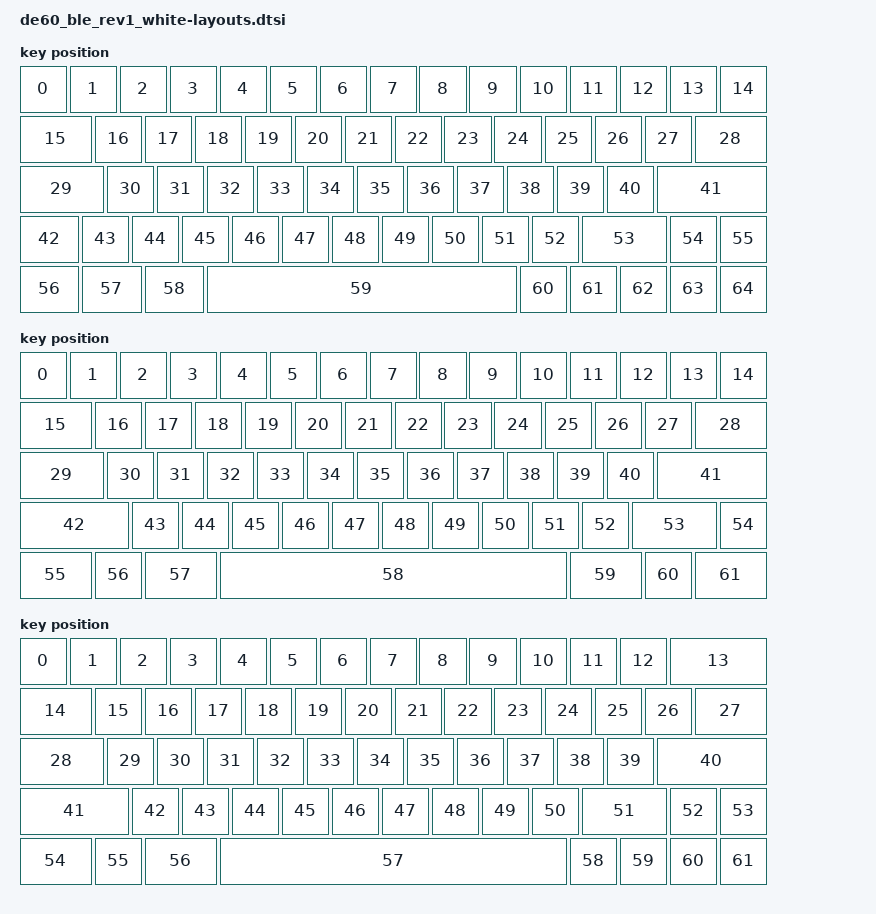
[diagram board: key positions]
#include <physical_layouts.dtsi>

/ {

    chosen {
        zmk,physical-layout = &white_ansi_625u;
    };

    white_all: white_all {
        compatible = "zmk,physical-layout";
        display-name = "WHITE All";

        kscan = <&kscan0>;
        transform = <&white_all_transform>;

        keys  //                     w   h    x    y     rot    rx    ry
            = <&key_physical_attrs 100 100    0    0       0     0     0>
            , <&key_physical_attrs 100 100  100    0       0     0     0>
            , <&key_physical_attrs 100 100  200    0       0     0     0>
            , <&key_physical_attrs 100 100  300    0       0     0     0>
            , <&key_physical_attrs 100 100  400    0       0     0     0>
            , <&key_physical_attrs 100 100  500    0       0     0     0>
            , <&key_physical_attrs 100 100  600    0       0     0     0>
            , <&key_physical_attrs 100 100  700    0       0     0     0>
            , <&key_physical_attrs 100 100  800    0       0     0     0>
            , <&key_physical_attrs 100 100  900    0       0     0     0>
            , <&key_physical_attrs 100 100 1000    0       0     0     0>
            , <&key_physical_attrs 100 100 1100    0       0     0     0>
            , <&key_physical_attrs 100 100 1200    0       0     0     0>
            , <&key_physical_attrs 100 100 1300    0       0     0     0>
            , <&key_physical_attrs 100 100 1400    0       0     0     0>
            , <&key_physical_attrs 150 100    0  100       0     0     0>
            , <&key_physical_attrs 100 100  150  100       0     0     0>
            , <&key_physical_attrs 100 100  250  100       0     0     0>
            , <&key_physical_attrs 100 100  350  100       0     0     0>
            , <&key_physical_attrs 100 100  450  100       0     0     0>
            , <&key_physical_attrs 100 100  550  100       0     0     0>
            , <&key_physical_attrs 100 100  650  100       0     0     0>
            , <&key_physical_attrs 100 100  750  100       0     0     0>
            , <&key_physical_attrs 100 100  850  100       0     0     0>
            , <&key_physical_attrs 100 100  950  100       0     0     0>
            , <&key_physical_attrs 100 100 1050  100       0     0     0>
            , <&key_physical_attrs 100 100 1150  100       0     0     0>
            , <&key_physical_attrs 100 100 1250  100       0     0     0>
            , <&key_physical_attrs 150 100 1350  100       0     0     0>
            , <&key_physical_attrs 175 100    0  200       0     0     0>
            , <&key_physical_attrs 100 100  175  200       0     0     0>
            , <&key_physical_attrs 100 100  275  200       0     0     0>
            , <&key_physical_attrs 100 100  375  200       0     0     0>
            , <&key_physical_attrs 100 100  475  200       0     0     0>
            , <&key_physical_attrs 100 100  575  200       0     0     0>
            , <&key_physical_attrs 100 100  675  200       0     0     0>
            , <&key_physical_attrs 100 100  775  200       0     0     0>
            , <&key_physical_attrs 100 100  875  200       0     0     0>
            , <&key_physical_attrs 100 100  975  200       0     0     0>
            , <&key_physical_attrs 100 100 1075  200       0     0     0>
            , <&key_physical_attrs 100 100 1175  200       0     0     0>
            , <&key_physical_attrs 225 100 1275  200       0     0     0>
            , <&key_physical_attrs 125 100    0  300       0     0     0>
            , <&key_physical_attrs 100 100  125  300       0     0     0>
            , <&key_physical_attrs 100 100  225  300       0     0     0>
            , <&key_physical_attrs 100 100  325  300       0     0     0>
            , <&key_physical_attrs 100 100  425  300       0     0     0>
            , <&key_physical_attrs 100 100  525  300       0     0     0>
            , <&key_physical_attrs 100 100  625  300       0     0     0>
            , <&key_physical_attrs 100 100  725  300       0     0     0>
            , <&key_physical_attrs 100 100  825  300       0     0     0>
            , <&key_physical_attrs 100 100  925  300       0     0     0>
            , <&key_physical_attrs 100 100 1025  300       0     0     0>
            , <&key_physical_attrs 175 100 1125  300       0     0     0>
            , <&key_physical_attrs 100 100 1300  300       0     0     0>
            , <&key_physical_attrs 100 100 1400  300       0     0     0>
            , <&key_physical_attrs 125 100    0  400       0     0     0>
            , <&key_physical_attrs 125 100  125  400       0     0     0>
            , <&key_physical_attrs 125 100  250  400       0     0     0>
            , <&key_physical_attrs 625 100  375  400       0     0     0>
            , <&key_physical_attrs 100 100 1000  400       0     0     0>
            , <&key_physical_attrs 100 100 1100  400       0     0     0>
            , <&key_physical_attrs 100 100 1200  400       0     0     0>
            , <&key_physical_attrs 100 100 1300  400       0     0     0>
            , <&key_physical_attrs 100 100 1400  400       0     0     0>
            ;
    };

    white_tsangan_split_bs_rshift: white_tsangan_split_bs_rshift {
        compatible = "zmk,physical-layout";
        display-name = "ANSI + 7U Tsangan | BS Split | Shift Tsangan";
        transform = <&white_ansi_tsangan_split_bs_rshift_transform>;

        keys  //                     w   h    x    y     rot    rx    ry
            = <&key_physical_attrs 100 100    0    0       0     0     0>
            , <&key_physical_attrs 100 100  100    0       0     0     0>
            , <&key_physical_attrs 100 100  200    0       0     0     0>
            , <&key_physical_attrs 100 100  300    0       0     0     0>
            , <&key_physical_attrs 100 100  400    0       0     0     0>
            , <&key_physical_attrs 100 100  500    0       0     0     0>
            , <&key_physical_attrs 100 100  600    0       0     0     0>
            , <&key_physical_attrs 100 100  700    0       0     0     0>
            , <&key_physical_attrs 100 100  800    0       0     0     0>
            , <&key_physical_attrs 100 100  900    0       0     0     0>
            , <&key_physical_attrs 100 100 1000    0       0     0     0>
            , <&key_physical_attrs 100 100 1100    0       0     0     0>
            , <&key_physical_attrs 100 100 1200    0       0     0     0>
            , <&key_physical_attrs 100 100 1300    0       0     0     0>
            , <&key_physical_attrs 100 100 1400    0       0     0     0>
            , <&key_physical_attrs 150 100    0  100       0     0     0>
            , <&key_physical_attrs 100 100  150  100       0     0     0>
            , <&key_physical_attrs 100 100  250  100       0     0     0>
            , <&key_physical_attrs 100 100  350  100       0     0     0>
            , <&key_physical_attrs 100 100  450  100       0     0     0>
            , <&key_physical_attrs 100 100  550  100       0     0     0>
            , <&key_physical_attrs 100 100  650  100       0     0     0>
            , <&key_physical_attrs 100 100  750  100       0     0     0>
            , <&key_physical_attrs 100 100  850  100       0     0     0>
            , <&key_physical_attrs 100 100  950  100       0     0     0>
            , <&key_physical_attrs 100 100 1050  100       0     0     0>
            , <&key_physical_attrs 100 100 1150  100       0     0     0>
            , <&key_physical_attrs 100 100 1250  100       0     0     0>
            , <&key_physical_attrs 150 100 1350  100       0     0     0>
            , <&key_physical_attrs 175 100    0  200       0     0     0>
            , <&key_physical_attrs 100 100  175  200       0     0     0>
            , <&key_physical_attrs 100 100  275  200       0     0     0>
            , <&key_physical_attrs 100 100  375  200       0     0     0>
            , <&key_physical_attrs 100 100  475  200       0     0     0>
            , <&key_physical_attrs 100 100  575  200       0     0     0>
            , <&key_physical_attrs 100 100  675  200       0     0     0>
            , <&key_physical_attrs 100 100  775  200       0     0     0>
            , <&key_physical_attrs 100 100  875  200       0     0     0>
            , <&key_physical_attrs 100 100  975  200       0     0     0>
            , <&key_physical_attrs 100 100 1075  200       0     0     0>
            , <&key_physical_attrs 100 100 1175  200       0     0     0>
            , <&key_physical_attrs 225 100 1275  200       0     0     0>
            , <&key_physical_attrs 225 100    0  300       0     0     0>
            , <&key_physical_attrs 100 100  225  300       0     0     0>
            , <&key_physical_attrs 100 100  325  300       0     0     0>
            , <&key_physical_attrs 100 100  425  300       0     0     0>
            , <&key_physical_attrs 100 100  525  300       0     0     0>
            , <&key_physical_attrs 100 100  625  300       0     0     0>
            , <&key_physical_attrs 100 100  725  300       0     0     0>
            , <&key_physical_attrs 100 100  825  300       0     0     0>
            , <&key_physical_attrs 100 100  925  300       0     0     0>
            , <&key_physical_attrs 100 100 1025  300       0     0     0>
            , <&key_physical_attrs 100 100 1125  300       0     0     0>
            , <&key_physical_attrs 175 100 1225  300       0     0     0>
            , <&key_physical_attrs 100 100 1400  300       0     0     0>
            , <&key_physical_attrs 150 100    0  400       0     0     0>
            , <&key_physical_attrs 100 100  150  400       0     0     0>
            , <&key_physical_attrs 150 100  250  400       0     0     0>
            , <&key_physical_attrs 700 100  400  400       0     0     0>
            , <&key_physical_attrs 150 100 1100  400       0     0     0>
            , <&key_physical_attrs 100 100 1250  400       0     0     0>
            , <&key_physical_attrs 150 100 1350  400       0     0     0>
            ;
    };

    white_tsangan_arrow: white_tsangan_arrow {
        compatible = "zmk,physical-layout";
        display-name = "ANSI + 7U Arrow | BS 2U | Shift Arrow";

        kscan = <&kscan0>;
        transform = <&white_ansi_tsangan_arrow_transform>;

        keys  //                     w   h    x    y     rot    rx    ry
            = <&key_physical_attrs 100 100    0    0       0     0     0>
            , <&key_physical_attrs 100 100  100    0       0     0     0>
            , <&key_physical_attrs 100 100  200    0       0     0     0>
            , <&key_physical_attrs 100 100  300    0       0     0     0>
            , <&key_physical_attrs 100 100  400    0       0     0     0>
            , <&key_physical_attrs 100 100  500    0       0     0     0>
            , <&key_physical_attrs 100 100  600    0       0     0     0>
            , <&key_physical_attrs 100 100  700    0       0     0     0>
            , <&key_physical_attrs 100 100  800    0       0     0     0>
            , <&key_physical_attrs 100 100  900    0       0     0     0>
            , <&key_physical_attrs 100 100 1000    0       0     0     0>
            , <&key_physical_attrs 100 100 1100    0       0     0     0>
            , <&key_physical_attrs 100 100 1200    0       0     0     0>
            , <&key_physical_attrs 200 100 1300    0       0     0     0>
            , <&key_physical_attrs 150 100    0  100       0     0     0>
            , <&key_physical_attrs 100 100  150  100       0     0     0>
            , <&key_physical_attrs 100 100  250  100       0     0     0>
            , <&key_physical_attrs 100 100  350  100       0     0     0>
            , <&key_physical_attrs 100 100  450  100       0     0     0>
            , <&key_physical_attrs 100 100  550  100       0     0     0>
            , <&key_physical_attrs 100 100  650  100       0     0     0>
            , <&key_physical_attrs 100 100  750  100       0     0     0>
            , <&key_physical_attrs 100 100  850  100       0     0     0>
            , <&key_physical_attrs 100 100  950  100       0     0     0>
            , <&key_physical_attrs 100 100 1050  100       0     0     0>
            , <&key_physical_attrs 100 100 1150  100       0     0     0>
            , <&key_physical_attrs 100 100 1250  100       0     0     0>
            , <&key_physical_attrs 150 100 1350  100       0     0     0>
            , <&key_physical_attrs 175 100    0  200       0     0     0>
            , <&key_physical_attrs 100 100  175  200       0     0     0>
            , <&key_physical_attrs 100 100  275  200       0     0     0>
            , <&key_physical_attrs 100 100  375  200       0     0     0>
            , <&key_physical_attrs 100 100  475  200       0     0     0>
            , <&key_physical_attrs 100 100  575  200       0     0     0>
            , <&key_physical_attrs 100 100  675  200       0     0     0>
            , <&key_physical_attrs 100 100  775  200       0     0     0>
            , <&key_physical_attrs 100 100  875  200       0     0     0>
            , <&key_physical_attrs 100 100  975  200       0     0     0>
            , <&key_physical_attrs 100 100 1075  200       0     0     0>
            , <&key_physical_attrs 100 100 1175  200       0     0     0>
            , <&key_physical_attrs 225 100 1275  200       0     0     0>
            , <&key_physical_attrs 225 100    0  300       0     0     0>
            , <&key_physical_attrs 100 100  225  300       0     0     0>
            , <&key_physical_attrs 100 100  325  300       0     0     0>
            , <&key_physical_attrs 100 100  425  300       0     0     0>
            , <&key_physical_attrs 100 100  525  300       0     0     0>
            , <&key_physical_attrs 100 100  625  300       0     0     0>
            , <&key_physical_attrs 100 100  725  300       0     0     0>
            , <&key_physical_attrs 100 100  825  300       0     0     0>
            , <&key_physical_attrs 100 100  925  300       0     0     0>
            , <&key_physical_attrs 100 100 1025  300       0     0     0>
            , <&key_physical_attrs 175 100 1125  300       0     0     0>
            , <&key_physical_attrs 100 100 1300  300       0     0     0>
            , <&key_physical_attrs 100 100 1400  300       0     0     0>
            , <&key_physical_attrs 150 100    0  400       0     0     0>
            , <&key_physical_attrs 100 100  150  400       0     0     0>
            , <&key_physical_attrs 150 100  250  400       0     0     0>
            , <&key_physical_attrs 700 100  400  400       0     0     0>
            , <&key_physical_attrs 100 100 1100  400       0     0     0>
            , <&key_physical_attrs 100 100 1200  400       0     0     0>
            , <&key_physical_attrs 100 100 1300  400       0     0     0>
            , <&key_physical_attrs 100 100 1400  400       0     0     0>
            ;
    };

    white_tsangan_arrow_split_bs: white_tsangan_arrow_split_bs {
        compatible = "zmk,physical-layout";
        display-name = "ANSI + 7U Arrow | BS Split | Shift Arrow";

        kscan = <&kscan0>;
        transform = <&white_ansi_tsangan_arrow_split_bs_transform>;

        keys  //                     w   h    x    y     rot    rx    ry
            = <&key_physical_attrs 100 100    0    0       0     0     0>
            , <&key_physical_attrs 100 100  100    0       0     0     0>
            , <&key_physical_attrs 100 100  200    0       0     0     0>
            , <&key_physical_attrs 100 100  300    0       0     0     0>
            , <&key_physical_attrs 100 100  400    0       0     0     0>
            , <&key_physical_attrs 100 100  500    0       0     0     0>
            , <&key_physical_attrs 100 100  600    0       0     0     0>
            , <&key_physical_attrs 100 100  700    0       0     0     0>
            , <&key_physical_attrs 100 100  800    0       0     0     0>
            , <&key_physical_attrs 100 100  900    0       0     0     0>
            , <&key_physical_attrs 100 100 1000    0       0     0     0>
            , <&key_physical_attrs 100 100 1100    0       0     0     0>
            , <&key_physical_attrs 100 100 1200    0       0     0     0>
            , <&key_physical_attrs 100 100 1300    0       0     0     0>
            , <&key_physical_attrs 100 100 1400    0       0     0     0>
            , <&key_physical_attrs 150 100    0  100       0     0     0>
            , <&key_physical_attrs 100 100  150  100       0     0     0>
            , <&key_physical_attrs 100 100  250  100       0     0     0>
            , <&key_physical_attrs 100 100  350  100       0     0     0>
            , <&key_physical_attrs 100 100  450  100       0     0     0>
            , <&key_physical_attrs 100 100  550  100       0     0     0>
            , <&key_physical_attrs 100 100  650  100       0     0     0>
            , <&key_physical_attrs 100 100  750  100       0     0     0>
            , <&key_physical_attrs 100 100  850  100       0     0     0>
            , <&key_physical_attrs 100 100  950  100       0     0     0>
            , <&key_physical_attrs 100 100 1050  100       0     0     0>
            , <&key_physical_attrs 100 100 1150  100       0     0     0>
            , <&key_physical_attrs 100 100 1250  100       0     0     0>
            , <&key_physical_attrs 150 100 1350  100       0     0     0>
            , <&key_physical_attrs 175 100    0  200       0     0     0>
            , <&key_physical_attrs 100 100  175  200       0     0     0>
            , <&key_physical_attrs 100 100  275  200       0     0     0>
            , <&key_physical_attrs 100 100  375  200       0     0     0>
            , <&key_physical_attrs 100 100  475  200       0     0     0>
            , <&key_physical_attrs 100 100  575  200       0     0     0>
            , <&key_physical_attrs 100 100  675  200       0     0     0>
            , <&key_physical_attrs 100 100  775  200       0     0     0>
            , <&key_physical_attrs 100 100  875  200       0     0     0>
            , <&key_physical_attrs 100 100  975  200       0     0     0>
            , <&key_physical_attrs 100 100 1075  200       0     0     0>
            , <&key_physical_attrs 100 100 1175  200       0     0     0>
            , <&key_physical_attrs 225 100 1275  200       0     0     0>
            , <&key_physical_attrs 225 100    0  300       0     0     0>
            , <&key_physical_attrs 100 100  225  300       0     0     0>
            , <&key_physical_attrs 100 100  325  300       0     0     0>
            , <&key_physical_attrs 100 100  425  300       0     0     0>
            , <&key_physical_attrs 100 100  525  300       0     0     0>
            , <&key_physical_attrs 100 100  625  300       0     0     0>
            , <&key_physical_attrs 100 100  725  300       0     0     0>
            , <&key_physical_attrs 100 100  825  300       0     0     0>
            , <&key_physical_attrs 100 100  925  300       0     0     0>
            , <&key_physical_attrs 100 100 1025  300       0     0     0>
            , <&key_physical_attrs 175 100 1125  300       0     0     0>
            , <&key_physical_attrs 100 100 1300  300       0     0     0>
            , <&key_physical_attrs 100 100 1400  300       0     0     0>
            , <&key_physical_attrs 150 100    0  400       0     0     0>
            , <&key_physical_attrs 100 100  150  400       0     0     0>
            , <&key_physical_attrs 150 100  250  400       0     0     0>
            , <&key_physical_attrs 700 100  400  400       0     0     0>
            , <&key_physical_attrs 100 100 1100  400       0     0     0>
            , <&key_physical_attrs 100 100 1200  400       0     0     0>
            , <&key_physical_attrs 100 100 1300  400       0     0     0>
            , <&key_physical_attrs 100 100 1400  400       0     0     0>
            ;
    };

    white_ansi: white_ansi {
        compatible = "zmk,physical-layout";
        display-name = "ANSI + 6.25U Universal | BS 2U | Shift Universal";

        kscan = <&kscan0>;
        transform = <&white_ansi_transform>;

        keys  //                     w   h    x    y     rot    rx    ry
            = <&key_physical_attrs 100 100    0    0       0     0     0>
            , <&key_physical_attrs 100 100  100    0       0     0     0>
            , <&key_physical_attrs 100 100  200    0       0     0     0>
            , <&key_physical_attrs 100 100  300    0       0     0     0>
            , <&key_physical_attrs 100 100  400    0       0     0     0>
            , <&key_physical_attrs 100 100  500    0       0     0     0>
            , <&key_physical_attrs 100 100  600    0       0     0     0>
            , <&key_physical_attrs 100 100  700    0       0     0     0>
            , <&key_physical_attrs 100 100  800    0       0     0     0>
            , <&key_physical_attrs 100 100  900    0       0     0     0>
            , <&key_physical_attrs 100 100 1000    0       0     0     0>
            , <&key_physical_attrs 100 100 1100    0       0     0     0>
            , <&key_physical_attrs 100 100 1200    0       0     0     0>
            , <&key_physical_attrs 200 100 1300    0       0     0     0>
            , <&key_physical_attrs 150 100    0  100       0     0     0>
            , <&key_physical_attrs 100 100  150  100       0     0     0>
            , <&key_physical_attrs 100 100  250  100       0     0     0>
            , <&key_physical_attrs 100 100  350  100       0     0     0>
            , <&key_physical_attrs 100 100  450  100       0     0     0>
            , <&key_physical_attrs 100 100  550  100       0     0     0>
            , <&key_physical_attrs 100 100  650  100       0     0     0>
            , <&key_physical_attrs 100 100  750  100       0     0     0>
            , <&key_physical_attrs 100 100  850  100       0     0     0>
            , <&key_physical_attrs 100 100  950  100       0     0     0>
            , <&key_physical_attrs 100 100 1050  100       0     0     0>
            , <&key_physical_attrs 100 100 1150  100       0     0     0>
            , <&key_physical_attrs 100 100 1250  100       0     0     0>
            , <&key_physical_attrs 150 100 1350  100       0     0     0>
            , <&key_physical_attrs 175 100    0  200       0     0     0>
            , <&key_physical_attrs 100 100  175  200       0     0     0>
            , <&key_physical_attrs 100 100  275  200       0     0     0>
            , <&key_physical_attrs 100 100  375  200       0     0     0>
            , <&key_physical_attrs 100 100  475  200       0     0     0>
            , <&key_physical_attrs 100 100  575  200       0     0     0>
            , <&key_physical_attrs 100 100  675  200       0     0     0>
            , <&key_physical_attrs 100 100  775  200       0     0     0>
            , <&key_physical_attrs 100 100  875  200       0     0     0>
            , <&key_physical_attrs 100 100  975  200       0     0     0>
            , <&key_physical_attrs 100 100 1075  200       0     0     0>
            , <&key_physical_attrs 100 100 1175  200       0     0     0>
            , <&key_physical_attrs 225 100 1275  200       0     0     0>
            , <&key_physical_attrs 225 100    0  300       0     0     0>
            , <&key_physical_attrs 100 100  225  300       0     0     0>
            , <&key_physical_attrs 100 100  325  300       0     0     0>
            , <&key_physical_attrs 100 100  425  300       0     0     0>
            , <&key_physical_attrs 100 100  525  300       0     0     0>
            , <&key_physical_attrs 100 100  625  300       0     0     0>
            , <&key_physical_attrs 100 100  725  300       0     0     0>
            , <&key_physical_attrs 100 100  825  300       0     0     0>
            , <&key_physical_attrs 100 100  925  300       0     0     0>
            , <&key_physical_attrs 100 100 1025  300       0     0     0>
            , <&key_physical_attrs 100 100 1125  300       0     0     0>
            , <&key_physical_attrs 275 100 1225  300       0     0     0>
            , <&key_physical_attrs 125 100    0  400       0     0     0>
            , <&key_physical_attrs 125 100  125  400       0     0     0>
            , <&key_physical_attrs 125 100  250  400       0     0     0>
            , <&key_physical_attrs 625 100  375  400       0     0     0>
            , <&key_physical_attrs 125 100 1000  400       0     0     0>
            , <&key_physical_attrs 125 100 1125  400       0     0     0>
            , <&key_physical_attrs 125 100 1250  400       0     0     0>
            , <&key_physical_attrs 125 100 1375  400       0     0     0>
            ;
    };

    white_ansi_split_rshift: white_ansi_split_rshift {
        compatible = "zmk,physical-layout";
        display-name = "ANSI + 6.25U Universal | BS 2U | Shift Arrow";

        kscan = <&kscan0>;
        transform = <&white_ansi_split_rshift_transform>;

        keys  //                     w   h    x    y     rot    rx    ry
            = <&key_physical_attrs 100 100    0    0       0     0     0>
            , <&key_physical_attrs 100 100  100    0       0     0     0>
            , <&key_physical_attrs 100 100  200    0       0     0     0>
            , <&key_physical_attrs 100 100  300    0       0     0     0>
            , <&key_physical_attrs 100 100  400    0       0     0     0>
            , <&key_physical_attrs 100 100  500    0       0     0     0>
            , <&key_physical_attrs 100 100  600    0       0     0     0>
            , <&key_physical_attrs 100 100  700    0       0     0     0>
            , <&key_physical_attrs 100 100  800    0       0     0     0>
            , <&key_physical_attrs 100 100  900    0       0     0     0>
            , <&key_physical_attrs 100 100 1000    0       0     0     0>
            , <&key_physical_attrs 100 100 1100    0       0     0     0>
            , <&key_physical_attrs 100 100 1200    0       0     0     0>
            , <&key_physical_attrs 200 100 1300    0       0     0     0>
            , <&key_physical_attrs 150 100    0  100       0     0     0>
            , <&key_physical_attrs 100 100  150  100       0     0     0>
            , <&key_physical_attrs 100 100  250  100       0     0     0>
            , <&key_physical_attrs 100 100  350  100       0     0     0>
            , <&key_physical_attrs 100 100  450  100       0     0     0>
            , <&key_physical_attrs 100 100  550  100       0     0     0>
            , <&key_physical_attrs 100 100  650  100       0     0     0>
            , <&key_physical_attrs 100 100  750  100       0     0     0>
            , <&key_physical_attrs 100 100  850  100       0     0     0>
            , <&key_physical_attrs 100 100  950  100       0     0     0>
            , <&key_physical_attrs 100 100 1050  100       0     0     0>
            , <&key_physical_attrs 100 100 1150  100       0     0     0>
            , <&key_physical_attrs 100 100 1250  100       0     0     0>
            , <&key_physical_attrs 150 100 1350  100       0     0     0>
            , <&key_physical_attrs 175 100    0  200       0     0     0>
            , <&key_physical_attrs 100 100  175  200       0     0     0>
            , <&key_physical_attrs 100 100  275  200       0     0     0>
            , <&key_physical_attrs 100 100  375  200       0     0     0>
            , <&key_physical_attrs 100 100  475  200       0     0     0>
            , <&key_physical_attrs 100 100  575  200       0     0     0>
            , <&key_physical_attrs 100 100  675  200       0     0     0>
            , <&key_physical_attrs 100 100  775  200       0     0     0>
            , <&key_physical_attrs 100 100  875  200       0     0     0>
            , <&key_physical_attrs 100 100  975  200       0     0     0>
            , <&key_physical_attrs 100 100 1075  200       0     0     0>
            , <&key_physical_attrs 100 100 1175  200       0     0     0>
            , <&key_physical_attrs 225 100 1275  200       0     0     0>
            , <&key_physical_attrs 225 100    0  300       0     0     0>
            , <&key_physical_attrs 100 100  225  300       0     0     0>
            , <&key_physical_attrs 100 100  325  300       0     0     0>
            , <&key_physical_attrs 100 100  425  300       0     0     0>
            , <&key_physical_attrs 100 100  525  300       0     0     0>
            , <&key_physical_attrs 100 100  625  300       0     0     0>
            , <&key_physical_attrs 100 100  725  300       0     0     0>
            , <&key_physical_attrs 100 100  825  300       0     0     0>
            , <&key_physical_attrs 100 100  925  300       0     0     0>
            , <&key_physical_attrs 100 100 1025  300       0     0     0>
            , <&key_physical_attrs 100 100 1125  300       0     0     0>
            , <&key_physical_attrs 175 100 1225  300       0     0     0>
            , <&key_physical_attrs 100 100 1400  300       0     0     0>
            , <&key_physical_attrs 125 100    0  400       0     0     0>
            , <&key_physical_attrs 125 100  125  400       0     0     0>
            , <&key_physical_attrs 125 100  250  400       0     0     0>
            , <&key_physical_attrs 625 100  375  400       0     0     0>
            , <&key_physical_attrs 125 100 1000  400       0     0     0>
            , <&key_physical_attrs 125 100 1125  400       0     0     0>
            , <&key_physical_attrs 125 100 1250  400       0     0     0>
            , <&key_physical_attrs 125 100 1375  400       0     0     0>
            ;
    };

    both_ansi_10u_split_rshift: both_ansi_10u_split_rshift {
        compatible = "zmk,physical-layout";
        display-name = "ANSI + 10U Universal | BS 2U | Shift Universal";

        kscan = <&kscan0>;
        transform = <&both_ansi_10u_split_rshift_transform>;

        keys  //                     w   h    x    y     rot    rx    ry
            = <&key_physical_attrs 100 100    0    0       0     0     0>
            , <&key_physical_attrs 100 100  100    0       0     0     0>
            , <&key_physical_attrs 100 100  200    0       0     0     0>
            , <&key_physical_attrs 100 100  300    0       0     0     0>
            , <&key_physical_attrs 100 100  400    0       0     0     0>
            , <&key_physical_attrs 100 100  500    0       0     0     0>
            , <&key_physical_attrs 100 100  600    0       0     0     0>
            , <&key_physical_attrs 100 100  700    0       0     0     0>
            , <&key_physical_attrs 100 100  800    0       0     0     0>
            , <&key_physical_attrs 100 100  900    0       0     0     0>
            , <&key_physical_attrs 100 100 1000    0       0     0     0>
            , <&key_physical_attrs 100 100 1100    0       0     0     0>
            , <&key_physical_attrs 100 100 1200    0       0     0     0>
            , <&key_physical_attrs 200 100 1300    0       0     0     0>
            , <&key_physical_attrs 150 100    0  100       0     0     0>
            , <&key_physical_attrs 100 100  150  100       0     0     0>
            , <&key_physical_attrs 100 100  250  100       0     0     0>
            , <&key_physical_attrs 100 100  350  100       0     0     0>
            , <&key_physical_attrs 100 100  450  100       0     0     0>
            , <&key_physical_attrs 100 100  550  100       0     0     0>
            , <&key_physical_attrs 100 100  650  100       0     0     0>
            , <&key_physical_attrs 100 100  750  100       0     0     0>
            , <&key_physical_attrs 100 100  850  100       0     0     0>
            , <&key_physical_attrs 100 100  950  100       0     0     0>
            , <&key_physical_attrs 100 100 1050  100       0     0     0>
            , <&key_physical_attrs 100 100 1150  100       0     0     0>
            , <&key_physical_attrs 100 100 1250  100       0     0     0>
            , <&key_physical_attrs 150 100 1350  100       0     0     0>
            , <&key_physical_attrs 175 100    0  200       0     0     0>
            , <&key_physical_attrs 100 100  175  200       0     0     0>
            , <&key_physical_attrs 100 100  275  200       0     0     0>
            , <&key_physical_attrs 100 100  375  200       0     0     0>
            , <&key_physical_attrs 100 100  475  200       0     0     0>
            , <&key_physical_attrs 100 100  575  200       0     0     0>
            , <&key_physical_attrs 100 100  675  200       0     0     0>
            , <&key_physical_attrs 100 100  775  200       0     0     0>
            , <&key_physical_attrs 100 100  875  200       0     0     0>
            , <&key_physical_attrs 100 100  975  200       0     0     0>
            , <&key_physical_attrs 100 100 1075  200       0     0     0>
            , <&key_physical_attrs 100 100 1175  200       0     0     0>
            , <&key_physical_attrs 225 100 1275  200       0     0     0>
            , <&key_physical_attrs 225 100    0  300       0     0     0>
            , <&key_physical_attrs 100 100  225  300       0     0     0>
            , <&key_physical_attrs 100 100  325  300       0     0     0>
            , <&key_physical_attrs 100 100  425  300       0     0     0>
            , <&key_physical_attrs 100 100  525  300       0     0     0>
            , <&key_physical_attrs 100 100  625  300       0     0     0>
            , <&key_physical_attrs 100 100  725  300       0     0     0>
            , <&key_physical_attrs 100 100  825  300       0     0     0>
            , <&key_physical_attrs 100 100  925  300       0     0     0>
            , <&key_physical_attrs 100 100 1025  300       0     0     0>
            , <&key_physical_attrs 100 100 1125  300       0     0     0>
            , <&key_physical_attrs 175 100 1225  300       0     0     0>
            , <&key_physical_attrs 100 100 1400  300       0     0     0>
            , <&key_physical_attrs 150 100    0  400       0     0     0>
            , <&key_physical_attrs 100 100  150  400       0     0     0>
            , <&key_physical_attrs 1000 100  250  400       0     0     0>
            , <&key_physical_attrs 100 100 1250  400       0     0     0>
            , <&key_physical_attrs 150 100 1350  400       0     0     0>
            ;
    };

    both_ansi_10u_split_bs_rshift: both_ansi_10u_split_bs_rshift {
        compatible = "zmk,physical-layout";
        display-name = "ANSI + 10U Universal | BS Split | Shift Universal";

        kscan = <&kscan0>;
        transform = <&both_ansi_10u_split_bs_rshift_transform>;

        keys  //                     w   h    x    y     rot    rx    ry
            = <&key_physical_attrs 100 100    0    0       0     0     0>
            , <&key_physical_attrs 100 100  100    0       0     0     0>
            , <&key_physical_attrs 100 100  200    0       0     0     0>
            , <&key_physical_attrs 100 100  300    0       0     0     0>
            , <&key_physical_attrs 100 100  400    0       0     0     0>
            , <&key_physical_attrs 100 100  500    0       0     0     0>
            , <&key_physical_attrs 100 100  600    0       0     0     0>
            , <&key_physical_attrs 100 100  700    0       0     0     0>
            , <&key_physical_attrs 100 100  800    0       0     0     0>
            , <&key_physical_attrs 100 100  900    0       0     0     0>
            , <&key_physical_attrs 100 100 1000    0       0     0     0>
            , <&key_physical_attrs 100 100 1100    0       0     0     0>
            , <&key_physical_attrs 100 100 1200    0       0     0     0>
            , <&key_physical_attrs 100 100 1300    0       0     0     0>
            , <&key_physical_attrs 100 100 1400    0       0     0     0>
            , <&key_physical_attrs 150 100    0  100       0     0     0>
            , <&key_physical_attrs 100 100  150  100       0     0     0>
            , <&key_physical_attrs 100 100  250  100       0     0     0>
            , <&key_physical_attrs 100 100  350  100       0     0     0>
            , <&key_physical_attrs 100 100  450  100       0     0     0>
            , <&key_physical_attrs 100 100  550  100       0     0     0>
            , <&key_physical_attrs 100 100  650  100       0     0     0>
            , <&key_physical_attrs 100 100  750  100       0     0     0>
            , <&key_physical_attrs 100 100  850  100       0     0     0>
            , <&key_physical_attrs 100 100  950  100       0     0     0>
            , <&key_physical_attrs 100 100 1050  100       0     0     0>
            , <&key_physical_attrs 100 100 1150  100       0     0     0>
            , <&key_physical_attrs 100 100 1250  100       0     0     0>
            , <&key_physical_attrs 150 100 1350  100       0     0     0>
            , <&key_physical_attrs 175 100    0  200       0     0     0>
            , <&key_physical_attrs 100 100  175  200       0     0     0>
            , <&key_physical_attrs 100 100  275  200       0     0     0>
            , <&key_physical_attrs 100 100  375  200       0     0     0>
            , <&key_physical_attrs 100 100  475  200       0     0     0>
            , <&key_physical_attrs 100 100  575  200       0     0     0>
            , <&key_physical_attrs 100 100  675  200       0     0     0>
            , <&key_physical_attrs 100 100  775  200       0     0     0>
            , <&key_physical_attrs 100 100  875  200       0     0     0>
            , <&key_physical_attrs 100 100  975  200       0     0     0>
            , <&key_physical_attrs 100 100 1075  200       0     0     0>
            , <&key_physical_attrs 100 100 1175  200       0     0     0>
            , <&key_physical_attrs 225 100 1275  200       0     0     0>
            , <&key_physical_attrs 225 100    0  300       0     0     0>
            , <&key_physical_attrs 100 100  225  300       0     0     0>
            , <&key_physical_attrs 100 100  325  300       0     0     0>
            , <&key_physical_attrs 100 100  425  300       0     0     0>
            , <&key_physical_attrs 100 100  525  300       0     0     0>
            , <&key_physical_attrs 100 100  625  300       0     0     0>
            , <&key_physical_attrs 100 100  725  300       0     0     0>
            , <&key_physical_attrs 100 100  825  300       0     0     0>
            , <&key_physical_attrs 100 100  925  300       0     0     0>
            , <&key_physical_attrs 100 100 1025  300       0     0     0>
            , <&key_physical_attrs 100 100 1125  300       0     0     0>
            , <&key_physical_attrs 175 100 1225  300       0     0     0>
            , <&key_physical_attrs 100 100 1400  300       0     0     0>
            , <&key_physical_attrs 150 100    0  400       0     0     0>
            , <&key_physical_attrs 100 100  150  400       0     0     0>
            , <&key_physical_attrs 1000 100  250  400       0     0     0>
            , <&key_physical_attrs 100 100 1250  400       0     0     0>
            , <&key_physical_attrs 150 100 1350  400       0     0     0>
            ;
    };


    white_ansi_625u: white_ansi_625u {
        compatible = "zmk,physical-layout";
        display-name = "ANSI + 6.25U Universal | BS 2U | Shift Universal (Alias)";

        kscan = <&kscan0>;
        transform = <&white_ansi_transform>;

        keys  //                     w   h    x    y     rot    rx    ry
            = <&key_physical_attrs 100 100    0    0       0     0     0>
            , <&key_physical_attrs 100 100  100    0       0     0     0>
            , <&key_physical_attrs 100 100  200    0       0     0     0>
            , <&key_physical_attrs 100 100  300    0       0     0     0>
            , <&key_physical_attrs 100 100  400    0       0     0     0>
            , <&key_physical_attrs 100 100  500    0       0     0     0>
            , <&key_physical_attrs 100 100  600    0       0     0     0>
            , <&key_physical_attrs 100 100  700    0       0     0     0>
            , <&key_physical_attrs 100 100  800    0       0     0     0>
            , <&key_physical_attrs 100 100  900    0       0     0     0>
            , <&key_physical_attrs 100 100 1000    0       0     0     0>
            , <&key_physical_attrs 100 100 1100    0       0     0     0>
            , <&key_physical_attrs 100 100 1200    0       0     0     0>
            , <&key_physical_attrs 200 100 1300    0       0     0     0>
            , <&key_physical_attrs 150 100    0  100       0     0     0>
            , <&key_physical_attrs 100 100  150  100       0     0     0>
            , <&key_physical_attrs 100 100  250  100       0     0     0>
            , <&key_physical_attrs 100 100  350  100       0     0     0>
            , <&key_physical_attrs 100 100  450  100       0     0     0>
            , <&key_physical_attrs 100 100  550  100       0     0     0>
            , <&key_physical_attrs 100 100  650  100       0     0     0>
            , <&key_physical_attrs 100 100  750  100       0     0     0>
            , <&key_physical_attrs 100 100  850  100       0     0     0>
            , <&key_physical_attrs 100 100  950  100       0     0     0>
            , <&key_physical_attrs 100 100 1050  100       0     0     0>
            , <&key_physical_attrs 100 100 1150  100       0     0     0>
            , <&key_physical_attrs 100 100 1250  100       0     0     0>
            , <&key_physical_attrs 150 100 1350  100       0     0     0>
            , <&key_physical_attrs 175 100    0  200       0     0     0>
            , <&key_physical_attrs 100 100  175  200       0     0     0>
            , <&key_physical_attrs 100 100  275  200       0     0     0>
            , <&key_physical_attrs 100 100  375  200       0     0     0>
            , <&key_physical_attrs 100 100  475  200       0     0     0>
            , <&key_physical_attrs 100 100  575  200       0     0     0>
            , <&key_physical_attrs 100 100  675  200       0     0     0>
            , <&key_physical_attrs 100 100  775  200       0     0     0>
            , <&key_physical_attrs 100 100  875  200       0     0     0>
            , <&key_physical_attrs 100 100  975  200       0     0     0>
            , <&key_physical_attrs 100 100 1075  200       0     0     0>
            , <&key_physical_attrs 100 100 1175  200       0     0     0>
            , <&key_physical_attrs 225 100 1275  200       0     0     0>
            , <&key_physical_attrs 225 100    0  300       0     0     0>
            , <&key_physical_attrs 100 100  225  300       0     0     0>
            , <&key_physical_attrs 100 100  325  300       0     0     0>
            , <&key_physical_attrs 100 100  425  300       0     0     0>
            , <&key_physical_attrs 100 100  525  300       0     0     0>
            , <&key_physical_attrs 100 100  625  300       0     0     0>
            , <&key_physical_attrs 100 100  725  300       0     0     0>
            , <&key_physical_attrs 100 100  825  300       0     0     0>
            , <&key_physical_attrs 100 100  925  300       0     0     0>
            , <&key_physical_attrs 100 100 1025  300       0     0     0>
            , <&key_physical_attrs 100 100 1125  300       0     0     0>
            , <&key_physical_attrs 275 100 1225  300       0     0     0>
            , <&key_physical_attrs 125 100    0  400       0     0     0>
            , <&key_physical_attrs 125 100  125  400       0     0     0>
            , <&key_physical_attrs 125 100  250  400       0     0     0>
            , <&key_physical_attrs 625 100  375  400       0     0     0>
            , <&key_physical_attrs 125 100 1000  400       0     0     0>
            , <&key_physical_attrs 125 100 1125  400       0     0     0>
            , <&key_physical_attrs 125 100 1250  400       0     0     0>
            , <&key_physical_attrs 125 100 1375  400       0     0     0>
            ;
    };


    white_ansi_7u: white_ansi_7u {
        compatible = "zmk,physical-layout";
        display-name = "ANSI + 7U Arrow | BS 2U | Shift Arrow (Alias)";

        kscan = <&kscan0>;
        transform = <&white_ansi_tsangan_arrow_transform>;

        keys  //                     w   h    x    y     rot    rx    ry
            = <&key_physical_attrs 100 100    0    0       0     0     0>
            , <&key_physical_attrs 100 100  100    0       0     0     0>
            , <&key_physical_attrs 100 100  200    0       0     0     0>
            , <&key_physical_attrs 100 100  300    0       0     0     0>
            , <&key_physical_attrs 100 100  400    0       0     0     0>
            , <&key_physical_attrs 100 100  500    0       0     0     0>
            , <&key_physical_attrs 100 100  600    0       0     0     0>
            , <&key_physical_attrs 100 100  700    0       0     0     0>
            , <&key_physical_attrs 100 100  800    0       0     0     0>
            , <&key_physical_attrs 100 100  900    0       0     0     0>
            , <&key_physical_attrs 100 100 1000    0       0     0     0>
            , <&key_physical_attrs 100 100 1100    0       0     0     0>
            , <&key_physical_attrs 100 100 1200    0       0     0     0>
            , <&key_physical_attrs 200 100 1300    0       0     0     0>
            , <&key_physical_attrs 150 100    0  100       0     0     0>
            , <&key_physical_attrs 100 100  150  100       0     0     0>
            , <&key_physical_attrs 100 100  250  100       0     0     0>
            , <&key_physical_attrs 100 100  350  100       0     0     0>
            , <&key_physical_attrs 100 100  450  100       0     0     0>
            , <&key_physical_attrs 100 100  550  100       0     0     0>
            , <&key_physical_attrs 100 100  650  100       0     0     0>
            , <&key_physical_attrs 100 100  750  100       0     0     0>
            , <&key_physical_attrs 100 100  850  100       0     0     0>
            , <&key_physical_attrs 100 100  950  100       0     0     0>
            , <&key_physical_attrs 100 100 1050  100       0     0     0>
            , <&key_physical_attrs 100 100 1150  100       0     0     0>
            , <&key_physical_attrs 100 100 1250  100       0     0     0>
            , <&key_physical_attrs 150 100 1350  100       0     0     0>
            , <&key_physical_attrs 175 100    0  200       0     0     0>
            , <&key_physical_attrs 100 100  175  200       0     0     0>
            , <&key_physical_attrs 100 100  275  200       0     0     0>
            , <&key_physical_attrs 100 100  375  200       0     0     0>
            , <&key_physical_attrs 100 100  475  200       0     0     0>
            , <&key_physical_attrs 100 100  575  200       0     0     0>
            , <&key_physical_attrs 100 100  675  200       0     0     0>
            , <&key_physical_attrs 100 100  775  200       0     0     0>
            , <&key_physical_attrs 100 100  875  200       0     0     0>
            , <&key_physical_attrs 100 100  975  200       0     0     0>
            , <&key_physical_attrs 100 100 1075  200       0     0     0>
            , <&key_physical_attrs 100 100 1175  200       0     0     0>
            , <&key_physical_attrs 225 100 1275  200       0     0     0>
            , <&key_physical_attrs 225 100    0  300       0     0     0>
            , <&key_physical_attrs 100 100  225  300       0     0     0>
            , <&key_physical_attrs 100 100  325  300       0     0     0>
            , <&key_physical_attrs 100 100  425  300       0     0     0>
            , <&key_physical_attrs 100 100  525  300       0     0     0>
            , <&key_physical_attrs 100 100  625  300       0     0     0>
            , <&key_physical_attrs 100 100  725  300       0     0     0>
            , <&key_physical_attrs 100 100  825  300       0     0     0>
            , <&key_physical_attrs 100 100  925  300       0     0     0>
            , <&key_physical_attrs 100 100 1025  300       0     0     0>
            , <&key_physical_attrs 175 100 1125  300       0     0     0>
            , <&key_physical_attrs 100 100 1300  300       0     0     0>
            , <&key_physical_attrs 100 100 1400  300       0     0     0>
            , <&key_physical_attrs 150 100    0  400       0     0     0>
            , <&key_physical_attrs 100 100  150  400       0     0     0>
            , <&key_physical_attrs 150 100  250  400       0     0     0>
            , <&key_physical_attrs 700 100  400  400       0     0     0>
            , <&key_physical_attrs 100 100 1100  400       0     0     0>
            , <&key_physical_attrs 100 100 1200  400       0     0     0>
            , <&key_physical_attrs 100 100 1300  400       0     0     0>
            , <&key_physical_attrs 100 100 1400  400       0     0     0>
            ;
    };


    white_iso_625u: white_iso_625u {
        compatible = "zmk,physical-layout";
        display-name = "ISO + 6.25U Universal | BS 2U | Shift Universal";

        kscan = <&kscan0>;
        transform = <&white_ansi_transform>;

        keys  //                     w   h    x    y     rot    rx    ry
            = <&key_physical_attrs 100 100    0    0       0     0     0>
            , <&key_physical_attrs 100 100  100    0       0     0     0>
            , <&key_physical_attrs 100 100  200    0       0     0     0>
            , <&key_physical_attrs 100 100  300    0       0     0     0>
            , <&key_physical_attrs 100 100  400    0       0     0     0>
            , <&key_physical_attrs 100 100  500    0       0     0     0>
            , <&key_physical_attrs 100 100  600    0       0     0     0>
            , <&key_physical_attrs 100 100  700    0       0     0     0>
            , <&key_physical_attrs 100 100  800    0       0     0     0>
            , <&key_physical_attrs 100 100  900    0       0     0     0>
            , <&key_physical_attrs 100 100 1000    0       0     0     0>
            , <&key_physical_attrs 100 100 1100    0       0     0     0>
            , <&key_physical_attrs 100 100 1200    0       0     0     0>
            , <&key_physical_attrs 200 100 1300    0       0     0     0>
            , <&key_physical_attrs 150 100    0  100       0     0     0>
            , <&key_physical_attrs 100 100  150  100       0     0     0>
            , <&key_physical_attrs 100 100  250  100       0     0     0>
            , <&key_physical_attrs 100 100  350  100       0     0     0>
            , <&key_physical_attrs 100 100  450  100       0     0     0>
            , <&key_physical_attrs 100 100  550  100       0     0     0>
            , <&key_physical_attrs 100 100  650  100       0     0     0>
            , <&key_physical_attrs 100 100  750  100       0     0     0>
            , <&key_physical_attrs 100 100  850  100       0     0     0>
            , <&key_physical_attrs 100 100  950  100       0     0     0>
            , <&key_physical_attrs 100 100 1050  100       0     0     0>
            , <&key_physical_attrs 100 100 1150  100       0     0     0>
            , <&key_physical_attrs 100 100 1250  100       0     0     0>
            , <&key_physical_attrs 150 100 1350  100       0     0     0>
            , <&key_physical_attrs 175 100    0  200       0     0     0>
            , <&key_physical_attrs 100 100  175  200       0     0     0>
            , <&key_physical_attrs 100 100  275  200       0     0     0>
            , <&key_physical_attrs 100 100  375  200       0     0     0>
            , <&key_physical_attrs 100 100  475  200       0     0     0>
            , <&key_physical_attrs 100 100  575  200       0     0     0>
            , <&key_physical_attrs 100 100  675  200       0     0     0>
            , <&key_physical_attrs 100 100  775  200       0     0     0>
            , <&key_physical_attrs 100 100  875  200       0     0     0>
            , <&key_physical_attrs 100 100  975  200       0     0     0>
            , <&key_physical_attrs 100 100 1075  200       0     0     0>
            , <&key_physical_attrs 100 100 1175  200       0     0     0>
            , <&key_physical_attrs 225 100 1275  200       0     0     0>
            , <&key_physical_attrs 225 100    0  300       0     0     0>
            , <&key_physical_attrs 100 100  225  300       0     0     0>
            , <&key_physical_attrs 100 100  325  300       0     0     0>
            , <&key_physical_attrs 100 100  425  300       0     0     0>
            , <&key_physical_attrs 100 100  525  300       0     0     0>
            , <&key_physical_attrs 100 100  625  300       0     0     0>
            , <&key_physical_attrs 100 100  725  300       0     0     0>
            , <&key_physical_attrs 100 100  825  300       0     0     0>
            , <&key_physical_attrs 100 100  925  300       0     0     0>
            , <&key_physical_attrs 100 100 1025  300       0     0     0>
            , <&key_physical_attrs 100 100 1125  300       0     0     0>
            , <&key_physical_attrs 275 100 1225  300       0     0     0>
            , <&key_physical_attrs 125 100    0  400       0     0     0>
            , <&key_physical_attrs 125 100  125  400       0     0     0>
            , <&key_physical_attrs 125 100  250  400       0     0     0>
            , <&key_physical_attrs 625 100  375  400       0     0     0>
            , <&key_physical_attrs 125 100 1000  400       0     0     0>
            , <&key_physical_attrs 125 100 1125  400       0     0     0>
            , <&key_physical_attrs 125 100 1250  400       0     0     0>
            , <&key_physical_attrs 125 100 1375  400       0     0     0>
            ;
    };


    white_iso_7u: white_iso_7u {
        compatible = "zmk,physical-layout";
        display-name = "ISO + 7U Universal | BS 2U | Shift Universal";

        kscan = <&kscan0>;
        transform = <&white_ansi_tsangan_arrow_transform>;

        keys  //                     w   h    x    y     rot    rx    ry
            = <&key_physical_attrs 100 100    0    0       0     0     0>
            , <&key_physical_attrs 100 100  100    0       0     0     0>
            , <&key_physical_attrs 100 100  200    0       0     0     0>
            , <&key_physical_attrs 100 100  300    0       0     0     0>
            , <&key_physical_attrs 100 100  400    0       0     0     0>
            , <&key_physical_attrs 100 100  500    0       0     0     0>
            , <&key_physical_attrs 100 100  600    0       0     0     0>
            , <&key_physical_attrs 100 100  700    0       0     0     0>
            , <&key_physical_attrs 100 100  800    0       0     0     0>
            , <&key_physical_attrs 100 100  900    0       0     0     0>
            , <&key_physical_attrs 100 100 1000    0       0     0     0>
            , <&key_physical_attrs 100 100 1100    0       0     0     0>
            , <&key_physical_attrs 100 100 1200    0       0     0     0>
            , <&key_physical_attrs 200 100 1300    0       0     0     0>
            , <&key_physical_attrs 150 100    0  100       0     0     0>
            , <&key_physical_attrs 100 100  150  100       0     0     0>
            , <&key_physical_attrs 100 100  250  100       0     0     0>
            , <&key_physical_attrs 100 100  350  100       0     0     0>
            , <&key_physical_attrs 100 100  450  100       0     0     0>
            , <&key_physical_attrs 100 100  550  100       0     0     0>
            , <&key_physical_attrs 100 100  650  100       0     0     0>
            , <&key_physical_attrs 100 100  750  100       0     0     0>
            , <&key_physical_attrs 100 100  850  100       0     0     0>
            , <&key_physical_attrs 100 100  950  100       0     0     0>
            , <&key_physical_attrs 100 100 1050  100       0     0     0>
            , <&key_physical_attrs 100 100 1150  100       0     0     0>
            , <&key_physical_attrs 100 100 1250  100       0     0     0>
            , <&key_physical_attrs 150 100 1350  100       0     0     0>
            , <&key_physical_attrs 175 100    0  200       0     0     0>
            , <&key_physical_attrs 100 100  175  200       0     0     0>
            , <&key_physical_attrs 100 100  275  200       0     0     0>
            , <&key_physical_attrs 100 100  375  200       0     0     0>
            , <&key_physical_attrs 100 100  475  200       0     0     0>
            , <&key_physical_attrs 100 100  575  200       0     0     0>
            , <&key_physical_attrs 100 100  675  200       0     0     0>
            , <&key_physical_attrs 100 100  775  200       0     0     0>
            , <&key_physical_attrs 100 100  875  200       0     0     0>
            , <&key_physical_attrs 100 100  975  200       0     0     0>
            , <&key_physical_attrs 100 100 1075  200       0     0     0>
            , <&key_physical_attrs 100 100 1175  200       0     0     0>
            , <&key_physical_attrs 225 100 1275  200       0     0     0>
            , <&key_physical_attrs 225 100    0  300       0     0     0>
            , <&key_physical_attrs 100 100  225  300       0     0     0>
            , <&key_physical_attrs 100 100  325  300       0     0     0>
            , <&key_physical_attrs 100 100  425  300       0     0     0>
            , <&key_physical_attrs 100 100  525  300       0     0     0>
            , <&key_physical_attrs 100 100  625  300       0     0     0>
            , <&key_physical_attrs 100 100  725  300       0     0     0>
            , <&key_physical_attrs 100 100  825  300       0     0     0>
            , <&key_physical_attrs 100 100  925  300       0     0     0>
            , <&key_physical_attrs 100 100 1025  300       0     0     0>
            , <&key_physical_attrs 175 100 1125  300       0     0     0>
            , <&key_physical_attrs 100 100 1300  300       0     0     0>
            , <&key_physical_attrs 100 100 1400  300       0     0     0>
            , <&key_physical_attrs 150 100    0  400       0     0     0>
            , <&key_physical_attrs 100 100  150  400       0     0     0>
            , <&key_physical_attrs 150 100  250  400       0     0     0>
            , <&key_physical_attrs 700 100  400  400       0     0     0>
            , <&key_physical_attrs 100 100 1100  400       0     0     0>
            , <&key_physical_attrs 100 100 1200  400       0     0     0>
            , <&key_physical_attrs 100 100 1300  400       0     0     0>
            , <&key_physical_attrs 100 100 1400  400       0     0     0>
            ;
    };


    white_ansi_625u_hhkb: white_ansi_625u_hhkb {
        compatible = "zmk,physical-layout";
        display-name = "ANSI + 6.25U HHKB | BS 2U | Shift Universal";

        kscan = <&kscan0>;
        transform = <&white_ansi_625u_hhkb_transform>;

        keys  //                     w   h    x    y     rot    rx    ry
            = <&key_physical_attrs 100 100    0    0       0     0     0>
            , <&key_physical_attrs 100 100  100    0       0     0     0>
            , <&key_physical_attrs 100 100  200    0       0     0     0>
            , <&key_physical_attrs 100 100  300    0       0     0     0>
            , <&key_physical_attrs 100 100  400    0       0     0     0>
            , <&key_physical_attrs 100 100  500    0       0     0     0>
            , <&key_physical_attrs 100 100  600    0       0     0     0>
            , <&key_physical_attrs 100 100  700    0       0     0     0>
            , <&key_physical_attrs 100 100  800    0       0     0     0>
            , <&key_physical_attrs 100 100  900    0       0     0     0>
            , <&key_physical_attrs 100 100 1000    0       0     0     0>
            , <&key_physical_attrs 100 100 1100    0       0     0     0>
            , <&key_physical_attrs 100 100 1200    0       0     0     0>
            , <&key_physical_attrs 200 100 1300    0       0     0     0>
            , <&key_physical_attrs 150 100    0  100       0     0     0>
            , <&key_physical_attrs 100 100  150  100       0     0     0>
            , <&key_physical_attrs 100 100  250  100       0     0     0>
            , <&key_physical_attrs 100 100  350  100       0     0     0>
            , <&key_physical_attrs 100 100  450  100       0     0     0>
            , <&key_physical_attrs 100 100  550  100       0     0     0>
            , <&key_physical_attrs 100 100  650  100       0     0     0>
            , <&key_physical_attrs 100 100  750  100       0     0     0>
            , <&key_physical_attrs 100 100  850  100       0     0     0>
            , <&key_physical_attrs 100 100  950  100       0     0     0>
            , <&key_physical_attrs 100 100 1050  100       0     0     0>
            , <&key_physical_attrs 100 100 1150  100       0     0     0>
            , <&key_physical_attrs 100 100 1250  100       0     0     0>
            , <&key_physical_attrs 150 100 1350  100       0     0     0>
            , <&key_physical_attrs 175 100    0  200       0     0     0>
            , <&key_physical_attrs 100 100  175  200       0     0     0>
            , <&key_physical_attrs 100 100  275  200       0     0     0>
            , <&key_physical_attrs 100 100  375  200       0     0     0>
            , <&key_physical_attrs 100 100  475  200       0     0     0>
            , <&key_physical_attrs 100 100  575  200       0     0     0>
            , <&key_physical_attrs 100 100  675  200       0     0     0>
            , <&key_physical_attrs 100 100  775  200       0     0     0>
            , <&key_physical_attrs 100 100  875  200       0     0     0>
            , <&key_physical_attrs 100 100  975  200       0     0     0>
            , <&key_physical_attrs 100 100 1075  200       0     0     0>
            , <&key_physical_attrs 100 100 1175  200       0     0     0>
            , <&key_physical_attrs 225 100 1275  200       0     0     0>
            , <&key_physical_attrs 225 100    0  300       0     0     0>
            , <&key_physical_attrs 100 100  225  300       0     0     0>
            , <&key_physical_attrs 100 100  325  300       0     0     0>
            , <&key_physical_attrs 100 100  425  300       0     0     0>
            , <&key_physical_attrs 100 100  525  300       0     0     0>
            , <&key_physical_attrs 100 100  625  300       0     0     0>
            , <&key_physical_attrs 100 100  725  300       0     0     0>
            , <&key_physical_attrs 100 100  825  300       0     0     0>
            , <&key_physical_attrs 100 100  925  300       0     0     0>
            , <&key_physical_attrs 100 100 1025  300       0     0     0>
            , <&key_physical_attrs 100 100 1125  300       0     0     0>
            , <&key_physical_attrs 275 100 1225  300       0     0     0>
            , <&key_physical_attrs 100 100    0  400       0     0     0>
            , <&key_physical_attrs 150 100  100  400       0     0     0>
            , <&key_physical_attrs 625 100  250  400       0     0     0>
            , <&key_physical_attrs 125 100  875  400       0     0     0>
            , <&key_physical_attrs 125 100 1000  400       0     0     0>
            , <&key_physical_attrs 100 100 1125  400       0     0     0>
            ;
    };

    white_iso_625u_hhkb: white_iso_625u_hhkb {
        compatible = "zmk,physical-layout";
        display-name = "ISO + 6.25U HHKB | BS 2U | Shift Universal";

        kscan = <&kscan0>;
        transform = <&white_iso_625u_hhkb_transform>;

        keys  //                     w   h    x    y     rot    rx    ry
            = <&key_physical_attrs 100 100    0    0       0     0     0>
            , <&key_physical_attrs 100 100  100    0       0     0     0>
            , <&key_physical_attrs 100 100  200    0       0     0     0>
            , <&key_physical_attrs 100 100  300    0       0     0     0>
            , <&key_physical_attrs 100 100  400    0       0     0     0>
            , <&key_physical_attrs 100 100  500    0       0     0     0>
            , <&key_physical_attrs 100 100  600    0       0     0     0>
            , <&key_physical_attrs 100 100  700    0       0     0     0>
            , <&key_physical_attrs 100 100  800    0       0     0     0>
            , <&key_physical_attrs 100 100  900    0       0     0     0>
            , <&key_physical_attrs 100 100 1000    0       0     0     0>
            , <&key_physical_attrs 100 100 1100    0       0     0     0>
            , <&key_physical_attrs 100 100 1200    0       0     0     0>
            , <&key_physical_attrs 200 100 1300    0       0     0     0>
            , <&key_physical_attrs 150 100    0  100       0     0     0>
            , <&key_physical_attrs 100 100  150  100       0     0     0>
            , <&key_physical_attrs 100 100  250  100       0     0     0>
            , <&key_physical_attrs 100 100  350  100       0     0     0>
            , <&key_physical_attrs 100 100  450  100       0     0     0>
            , <&key_physical_attrs 100 100  550  100       0     0     0>
            , <&key_physical_attrs 100 100  650  100       0     0     0>
            , <&key_physical_attrs 100 100  750  100       0     0     0>
            , <&key_physical_attrs 100 100  850  100       0     0     0>
            , <&key_physical_attrs 100 100  950  100       0     0     0>
            , <&key_physical_attrs 100 100 1050  100       0     0     0>
            , <&key_physical_attrs 100 100 1150  100       0     0     0>
            , <&key_physical_attrs 100 100 1250  100       0     0     0>
            , <&key_physical_attrs 150 100 1350  100       0     0     0>
            , <&key_physical_attrs 175 100    0  200       0     0     0>
            , <&key_physical_attrs 100 100  175  200       0     0     0>
            , <&key_physical_attrs 100 100  275  200       0     0     0>
            , <&key_physical_attrs 100 100  375  200       0     0     0>
            , <&key_physical_attrs 100 100  475  200       0     0     0>
            , <&key_physical_attrs 100 100  575  200       0     0     0>
            , <&key_physical_attrs 100 100  675  200       0     0     0>
            , <&key_physical_attrs 100 100  775  200       0     0     0>
            , <&key_physical_attrs 100 100  875  200       0     0     0>
            , <&key_physical_attrs 100 100  975  200       0     0     0>
            , <&key_physical_attrs 100 100 1075  200       0     0     0>
            , <&key_physical_attrs 100 100 1175  200       0     0     0>
            , <&key_physical_attrs 225 100 1275  200       0     0     0>
            , <&key_physical_attrs 225 100    0  300       0     0     0>
            , <&key_physical_attrs 100 100  225  300       0     0     0>
            , <&key_physical_attrs 100 100  325  300       0     0     0>
            , <&key_physical_attrs 100 100  425  300       0     0     0>
            , <&key_physical_attrs 100 100  525  300       0     0     0>
            , <&key_physical_attrs 100 100  625  300       0     0     0>
            , <&key_physical_attrs 100 100  725  300       0     0     0>
            , <&key_physical_attrs 100 100  825  300       0     0     0>
            , <&key_physical_attrs 100 100  925  300       0     0     0>
            , <&key_physical_attrs 100 100 1025  300       0     0     0>
            , <&key_physical_attrs 100 100 1125  300       0     0     0>
            , <&key_physical_attrs 275 100 1225  300       0     0     0>
            , <&key_physical_attrs 100 100    0  400       0     0     0>
            , <&key_physical_attrs 150 100  100  400       0     0     0>
            , <&key_physical_attrs 625 100  250  400       0     0     0>
            , <&key_physical_attrs 125 100  875  400       0     0     0>
            , <&key_physical_attrs 125 100 1000  400       0     0     0>
            , <&key_physical_attrs 100 100 1125  400       0     0     0>
            ;
    };

    white_ansi_7u_hhkb: white_ansi_7u_hhkb {
        compatible = "zmk,physical-layout";
        display-name = "ANSI + 7U HHKB | BS 2U | Shift Universal";

        kscan = <&kscan0>;
        transform = <&white_ansi_7u_hhkb_transform>;

        keys  //                     w   h    x    y     rot    rx    ry
            = <&key_physical_attrs 100 100    0    0       0     0     0>
            , <&key_physical_attrs 100 100  100    0       0     0     0>
            , <&key_physical_attrs 100 100  200    0       0     0     0>
            , <&key_physical_attrs 100 100  300    0       0     0     0>
            , <&key_physical_attrs 100 100  400    0       0     0     0>
            , <&key_physical_attrs 100 100  500    0       0     0     0>
            , <&key_physical_attrs 100 100  600    0       0     0     0>
            , <&key_physical_attrs 100 100  700    0       0     0     0>
            , <&key_physical_attrs 100 100  800    0       0     0     0>
            , <&key_physical_attrs 100 100  900    0       0     0     0>
            , <&key_physical_attrs 100 100 1000    0       0     0     0>
            , <&key_physical_attrs 100 100 1100    0       0     0     0>
            , <&key_physical_attrs 100 100 1200    0       0     0     0>
            , <&key_physical_attrs 200 100 1300    0       0     0     0>
            , <&key_physical_attrs 150 100    0  100       0     0     0>
            , <&key_physical_attrs 100 100  150  100       0     0     0>
            , <&key_physical_attrs 100 100  250  100       0     0     0>
            , <&key_physical_attrs 100 100  350  100       0     0     0>
            , <&key_physical_attrs 100 100  450  100       0     0     0>
            , <&key_physical_attrs 100 100  550  100       0     0     0>
            , <&key_physical_attrs 100 100  650  100       0     0     0>
            , <&key_physical_attrs 100 100  750  100       0     0     0>
            , <&key_physical_attrs 100 100  850  100       0     0     0>
            , <&key_physical_attrs 100 100  950  100       0     0     0>
            , <&key_physical_attrs 100 100 1050  100       0     0     0>
            , <&key_physical_attrs 100 100 1150  100       0     0     0>
            , <&key_physical_attrs 100 100 1250  100       0     0     0>
            , <&key_physical_attrs 150 100 1350  100       0     0     0>
            , <&key_physical_attrs 175 100    0  200       0     0     0>
            , <&key_physical_attrs 100 100  175  200       0     0     0>
            , <&key_physical_attrs 100 100  275  200       0     0     0>
            , <&key_physical_attrs 100 100  375  200       0     0     0>
            , <&key_physical_attrs 100 100  475  200       0     0     0>
            , <&key_physical_attrs 100 100  575  200       0     0     0>
            , <&key_physical_attrs 100 100  675  200       0     0     0>
            , <&key_physical_attrs 100 100  775  200       0     0     0>
            , <&key_physical_attrs 100 100  875  200       0     0     0>
            , <&key_physical_attrs 100 100  975  200       0     0     0>
            , <&key_physical_attrs 100 100 1075  200       0     0     0>
            , <&key_physical_attrs 100 100 1175  200       0     0     0>
            , <&key_physical_attrs 225 100 1275  200       0     0     0>
            , <&key_physical_attrs 225 100    0  300       0     0     0>
            , <&key_physical_attrs 100 100  225  300       0     0     0>
            , <&key_physical_attrs 100 100  325  300       0     0     0>
            , <&key_physical_attrs 100 100  425  300       0     0     0>
            , <&key_physical_attrs 100 100  525  300       0     0     0>
            , <&key_physical_attrs 100 100  625  300       0     0     0>
            , <&key_physical_attrs 100 100  725  300       0     0     0>
            , <&key_physical_attrs 100 100  825  300       0     0     0>
            , <&key_physical_attrs 100 100  925  300       0     0     0>
            , <&key_physical_attrs 100 100 1025  300       0     0     0>
            , <&key_physical_attrs 175 100 1125  300       0     0     0>
            , <&key_physical_attrs 100 100 1300  300       0     0     0>
            , <&key_physical_attrs 100 100 1400  300       0     0     0>
            , <&key_physical_attrs 100 100    0  400       0     0     0>
            , <&key_physical_attrs 150 100  100  400       0     0     0>
            , <&key_physical_attrs 700 100  250  400       0     0     0>
            , <&key_physical_attrs 150 100  950  400       0     0     0>
            , <&key_physical_attrs 100 100 1100  400       0     0     0>
            ;
    };

    white_iso_7u_hhkb: white_iso_7u_hhkb {
        compatible = "zmk,physical-layout";
        display-name = "ISO + 7U HHKB | BS 2U | Shift Universal";

        kscan = <&kscan0>;
        transform = <&white_iso_7u_hhkb_transform>;

        keys  //                     w   h    x    y     rot    rx    ry
            = <&key_physical_attrs 100 100    0    0       0     0     0>
            , <&key_physical_attrs 100 100  100    0       0     0     0>
            , <&key_physical_attrs 100 100  200    0       0     0     0>
            , <&key_physical_attrs 100 100  300    0       0     0     0>
            , <&key_physical_attrs 100 100  400    0       0     0     0>
            , <&key_physical_attrs 100 100  500    0       0     0     0>
            , <&key_physical_attrs 100 100  600    0       0     0     0>
            , <&key_physical_attrs 100 100  700    0       0     0     0>
            , <&key_physical_attrs 100 100  800    0       0     0     0>
            , <&key_physical_attrs 100 100  900    0       0     0     0>
            , <&key_physical_attrs 100 100 1000    0       0     0     0>
            , <&key_physical_attrs 100 100 1100    0       0     0     0>
            , <&key_physical_attrs 100 100 1200    0       0     0     0>
            , <&key_physical_attrs 200 100 1300    0       0     0     0>
            , <&key_physical_attrs 150 100    0  100       0     0     0>
            , <&key_physical_attrs 100 100  150  100       0     0     0>
            , <&key_physical_attrs 100 100  250  100       0     0     0>
            , <&key_physical_attrs 100 100  350  100       0     0     0>
            , <&key_physical_attrs 100 100  450  100       0     0     0>
            , <&key_physical_attrs 100 100  550  100       0     0     0>
            , <&key_physical_attrs 100 100  650  100       0     0     0>
            , <&key_physical_attrs 100 100  750  100       0     0     0>
            , <&key_physical_attrs 100 100  850  100       0     0     0>
            , <&key_physical_attrs 100 100  950  100       0     0     0>
            , <&key_physical_attrs 100 100 1050  100       0     0     0>
            , <&key_physical_attrs 100 100 1150  100       0     0     0>
            , <&key_physical_attrs 100 100 1250  100       0     0     0>
            , <&key_physical_attrs 150 100 1350  100       0     0     0>
            , <&key_physical_attrs 175 100    0  200       0     0     0>
            , <&key_physical_attrs 100 100  175  200       0     0     0>
            , <&key_physical_attrs 100 100  275  200       0     0     0>
            , <&key_physical_attrs 100 100  375  200       0     0     0>
            , <&key_physical_attrs 100 100  475  200       0     0     0>
            , <&key_physical_attrs 100 100  575  200       0     0     0>
            , <&key_physical_attrs 100 100  675  200       0     0     0>
            , <&key_physical_attrs 100 100  775  200       0     0     0>
            , <&key_physical_attrs 100 100  875  200       0     0     0>
            , <&key_physical_attrs 100 100  975  200       0     0     0>
            , <&key_physical_attrs 100 100 1075  200       0     0     0>
            , <&key_physical_attrs 100 100 1175  200       0     0     0>
            , <&key_physical_attrs 225 100 1275  200       0     0     0>
            , <&key_physical_attrs 225 100    0  300       0     0     0>
            , <&key_physical_attrs 100 100  225  300       0     0     0>
            , <&key_physical_attrs 100 100  325  300       0     0     0>
            , <&key_physical_attrs 100 100  425  300       0     0     0>
            , <&key_physical_attrs 100 100  525  300       0     0     0>
            , <&key_physical_attrs 100 100  625  300       0     0     0>
            , <&key_physical_attrs 100 100  725  300       0     0     0>
            , <&key_physical_attrs 100 100  825  300       0     0     0>
            , <&key_physical_attrs 100 100  925  300       0     0     0>
            , <&key_physical_attrs 100 100 1025  300       0     0     0>
            , <&key_physical_attrs 175 100 1125  300       0     0     0>
            , <&key_physical_attrs 100 100 1300  300       0     0     0>
            , <&key_physical_attrs 100 100 1400  300       0     0     0>
            , <&key_physical_attrs 100 100    0  400       0     0     0>
            , <&key_physical_attrs 150 100  100  400       0     0     0>
            , <&key_physical_attrs 700 100  250  400       0     0     0>
            , <&key_physical_attrs 150 100  950  400       0     0     0>
            , <&key_physical_attrs 100 100 1100  400       0     0     0>
            ;
    };

    white_ansi_10u_hhkb: white_ansi_10u_hhkb {
        compatible = "zmk,physical-layout";
        display-name = "ANSI + 10U HHKB | BS 2U | Shift Universal";

        kscan = <&kscan0>;
        transform = <&white_ansi_10u_hhkb_transform>;

        keys  //                     w   h    x    y     rot    rx    ry
            = <&key_physical_attrs 100 100    0    0       0     0     0>
            , <&key_physical_attrs 100 100  100    0       0     0     0>
            , <&key_physical_attrs 100 100  200    0       0     0     0>
            , <&key_physical_attrs 100 100  300    0       0     0     0>
            , <&key_physical_attrs 100 100  400    0       0     0     0>
            , <&key_physical_attrs 100 100  500    0       0     0     0>
            , <&key_physical_attrs 100 100  600    0       0     0     0>
            , <&key_physical_attrs 100 100  700    0       0     0     0>
            , <&key_physical_attrs 100 100  800    0       0     0     0>
            , <&key_physical_attrs 100 100  900    0       0     0     0>
            , <&key_physical_attrs 100 100 1000    0       0     0     0>
            , <&key_physical_attrs 100 100 1100    0       0     0     0>
            , <&key_physical_attrs 100 100 1200    0       0     0     0>
            , <&key_physical_attrs 200 100 1300    0       0     0     0>
            , <&key_physical_attrs 150 100    0  100       0     0     0>
            , <&key_physical_attrs 100 100  150  100       0     0     0>
            , <&key_physical_attrs 100 100  250  100       0     0     0>
            , <&key_physical_attrs 100 100  350  100       0     0     0>
            , <&key_physical_attrs 100 100  450  100       0     0     0>
            , <&key_physical_attrs 100 100  550  100       0     0     0>
            , <&key_physical_attrs 100 100  650  100       0     0     0>
            , <&key_physical_attrs 100 100  750  100       0     0     0>
            , <&key_physical_attrs 100 100  850  100       0     0     0>
            , <&key_physical_attrs 100 100  950  100       0     0     0>
            , <&key_physical_attrs 100 100 1050  100       0     0     0>
            , <&key_physical_attrs 100 100 1150  100       0     0     0>
            , <&key_physical_attrs 100 100 1250  100       0     0     0>
            , <&key_physical_attrs 150 100 1350  100       0     0     0>
            , <&key_physical_attrs 175 100    0  200       0     0     0>
            , <&key_physical_attrs 100 100  175  200       0     0     0>
            , <&key_physical_attrs 100 100  275  200       0     0     0>
            , <&key_physical_attrs 100 100  375  200       0     0     0>
            , <&key_physical_attrs 100 100  475  200       0     0     0>
            , <&key_physical_attrs 100 100  575  200       0     0     0>
            , <&key_physical_attrs 100 100  675  200       0     0     0>
            , <&key_physical_attrs 100 100  775  200       0     0     0>
            , <&key_physical_attrs 100 100  875  200       0     0     0>
            , <&key_physical_attrs 100 100  975  200       0     0     0>
            , <&key_physical_attrs 100 100 1075  200       0     0     0>
            , <&key_physical_attrs 100 100 1175  200       0     0     0>
            , <&key_physical_attrs 225 100 1275  200       0     0     0>
            , <&key_physical_attrs 225 100    0  300       0     0     0>
            , <&key_physical_attrs 100 100  225  300       0     0     0>
            , <&key_physical_attrs 100 100  325  300       0     0     0>
            , <&key_physical_attrs 100 100  425  300       0     0     0>
            , <&key_physical_attrs 100 100  525  300       0     0     0>
            , <&key_physical_attrs 100 100  625  300       0     0     0>
            , <&key_physical_attrs 100 100  725  300       0     0     0>
            , <&key_physical_attrs 100 100  825  300       0     0     0>
            , <&key_physical_attrs 100 100  925  300       0     0     0>
            , <&key_physical_attrs 100 100 1025  300       0     0     0>
            , <&key_physical_attrs 100 100 1125  300       0     0     0>
            , <&key_physical_attrs 175 100 1225  300       0     0     0>
            , <&key_physical_attrs 100 100 1400  300       0     0     0>
            , <&key_physical_attrs 100 100    0  400       0     0     0>
            , <&key_physical_attrs 1000 100  100  400       0     0     0>
            , <&key_physical_attrs 100 100 1100  400       0     0     0>
            ;
    };

    white_iso_10u_hhkb: white_iso_10u_hhkb {
        compatible = "zmk,physical-layout";
        display-name = "ISO + 10U HHKB | BS 2U | Shift Universal";

        kscan = <&kscan0>;
        transform = <&white_iso_10u_hhkb_transform>;

        keys  //                     w   h    x    y     rot    rx    ry
            = <&key_physical_attrs 100 100    0    0       0     0     0>
            , <&key_physical_attrs 100 100  100    0       0     0     0>
            , <&key_physical_attrs 100 100  200    0       0     0     0>
            , <&key_physical_attrs 100 100  300    0       0     0     0>
            , <&key_physical_attrs 100 100  400    0       0     0     0>
            , <&key_physical_attrs 100 100  500    0       0     0     0>
            , <&key_physical_attrs 100 100  600    0       0     0     0>
            , <&key_physical_attrs 100 100  700    0       0     0     0>
            , <&key_physical_attrs 100 100  800    0       0     0     0>
            , <&key_physical_attrs 100 100  900    0       0     0     0>
            , <&key_physical_attrs 100 100 1000    0       0     0     0>
            , <&key_physical_attrs 100 100 1100    0       0     0     0>
            , <&key_physical_attrs 100 100 1200    0       0     0     0>
            , <&key_physical_attrs 200 100 1300    0       0     0     0>
            , <&key_physical_attrs 150 100    0  100       0     0     0>
            , <&key_physical_attrs 100 100  150  100       0     0     0>
            , <&key_physical_attrs 100 100  250  100       0     0     0>
            , <&key_physical_attrs 100 100  350  100       0     0     0>
            , <&key_physical_attrs 100 100  450  100       0     0     0>
            , <&key_physical_attrs 100 100  550  100       0     0     0>
            , <&key_physical_attrs 100 100  650  100       0     0     0>
            , <&key_physical_attrs 100 100  750  100       0     0     0>
            , <&key_physical_attrs 100 100  850  100       0     0     0>
            , <&key_physical_attrs 100 100  950  100       0     0     0>
            , <&key_physical_attrs 100 100 1050  100       0     0     0>
            , <&key_physical_attrs 100 100 1150  100       0     0     0>
            , <&key_physical_attrs 100 100 1250  100       0     0     0>
            , <&key_physical_attrs 150 100 1350  100       0     0     0>
            , <&key_physical_attrs 175 100    0  200       0     0     0>
            , <&key_physical_attrs 100 100  175  200       0     0     0>
            , <&key_physical_attrs 100 100  275  200       0     0     0>
            , <&key_physical_attrs 100 100  375  200       0     0     0>
            , <&key_physical_attrs 100 100  475  200       0     0     0>
            , <&key_physical_attrs 100 100  575  200       0     0     0>
            , <&key_physical_attrs 100 100  675  200       0     0     0>
            , <&key_physical_attrs 100 100  775  200       0     0     0>
            , <&key_physical_attrs 100 100  875  200       0     0     0>
            , <&key_physical_attrs 100 100  975  200       0     0     0>
            , <&key_physical_attrs 100 100 1075  200       0     0     0>
            , <&key_physical_attrs 100 100 1175  200       0     0     0>
            , <&key_physical_attrs 225 100 1275  200       0     0     0>
            , <&key_physical_attrs 225 100    0  300       0     0     0>
            , <&key_physical_attrs 100 100  225  300       0     0     0>
            , <&key_physical_attrs 100 100  325  300       0     0     0>
            , <&key_physical_attrs 100 100  425  300       0     0     0>
            , <&key_physical_attrs 100 100  525  300       0     0     0>
            , <&key_physical_attrs 100 100  625  300       0     0     0>
            , <&key_physical_attrs 100 100  725  300       0     0     0>
            , <&key_physical_attrs 100 100  825  300       0     0     0>
            , <&key_physical_attrs 100 100  925  300       0     0     0>
            , <&key_physical_attrs 100 100 1025  300       0     0     0>
            , <&key_physical_attrs 100 100 1125  300       0     0     0>
            , <&key_physical_attrs 175 100 1225  300       0     0     0>
            , <&key_physical_attrs 100 100 1400  300       0     0     0>
            , <&key_physical_attrs 100 100    0  400       0     0     0>
            , <&key_physical_attrs 1000 100  100  400       0     0     0>
            , <&key_physical_attrs 100 100 1100  400       0     0     0>
            ;
    };
    
    position_map {
        compatible = "zmk,physical-layout-position-map";

        white_all {
            physical-layout = <&white_all>;
            positions = <13 42 53 54 56 57 59 62 63 64>;
        };

        white_tsangan_split_bs_rshift {
            physical-layout = <&white_tsangan_split_bs_rshift>;
            positions = <13 42 52 53 55 56 58 59 60 61>;
        };

        white_tsangan_arrow {
            physical-layout = <&white_tsangan_arrow>;
            positions = <13 41 51 52 54 55 57 59 60 61>;
        };

        white_tsangan_arrow_split_bs {
            physical-layout = <&white_tsangan_arrow_split_bs>;
            positions = <13 42 52 53 55 56 58 60 61 62>;
        };

        white_ansi {
            physical-layout = <&white_ansi>;
            positions = <13 41 51 52 53 54 56 58 59 60>;
        };

        white_ansi_split_rshift {
            physical-layout = <&white_ansi_split_rshift>;
            positions = <13 41 51 52 54 55 57 59 60 61>;
        };

        both_ansi_10u_split_rshift {
            physical-layout = <&both_ansi_10u_split_rshift>;
            positions = <13 41 51 52 54 55 56 60 57 58>;
        };

        both_ansi_10u_split_bs_rshift {
            physical-layout = <&both_ansi_10u_split_bs_rshift>;
            positions = <13 42 52 53 55 56 57 60 58 59>;
        };

        white_ansi_625u {
            physical-layout = <&white_ansi_625u>;
            positions = <13 41 51 52 53 54 56 58 59 60>;
        };

        white_ansi_7u {
            physical-layout = <&white_ansi_7u>;
            positions = <13 41 51 52 54 55 57 59 60 61>;
        };

        white_iso_625u {
            physical-layout = <&white_iso_625u>;
            positions = <13 41 51 52 53 54 56 58 59 60>;
        };

        white_iso_7u {
            physical-layout = <&white_iso_7u>;
            positions = <13 41 51 52 54 55 57 59 60 61>;
        };

        white_ansi_625u_hhkb {
            physical-layout = <&white_ansi_625u_hhkb>;
            positions = <13 41 51 52 53 54 56 58 59 60>;
        };

        white_iso_625u_hhkb {
            physical-layout = <&white_iso_625u_hhkb>;
            positions = <13 41 51 52 53 54 56 58 59 60>;
        };

        white_ansi_7u_hhkb {
            physical-layout = <&white_ansi_7u_hhkb>;
            positions = <13 41 51 52 54 55 57 59 60 61>;
        };

        white_iso_7u_hhkb {
            physical-layout = <&white_iso_7u_hhkb>;
            positions = <13 41 51 52 54 55 57 59 60 61>;
        };

        white_ansi_10u_hhkb {
            physical-layout = <&white_ansi_10u_hhkb>;
            positions = <13 41 51 52 54 55 56 60 57 58>;
        };

        white_iso_10u_hhkb {
            physical-layout = <&white_iso_10u_hhkb>;
            positions = <13 41 51 52 54 55 56 60 57 58>;
        };
    };
};
